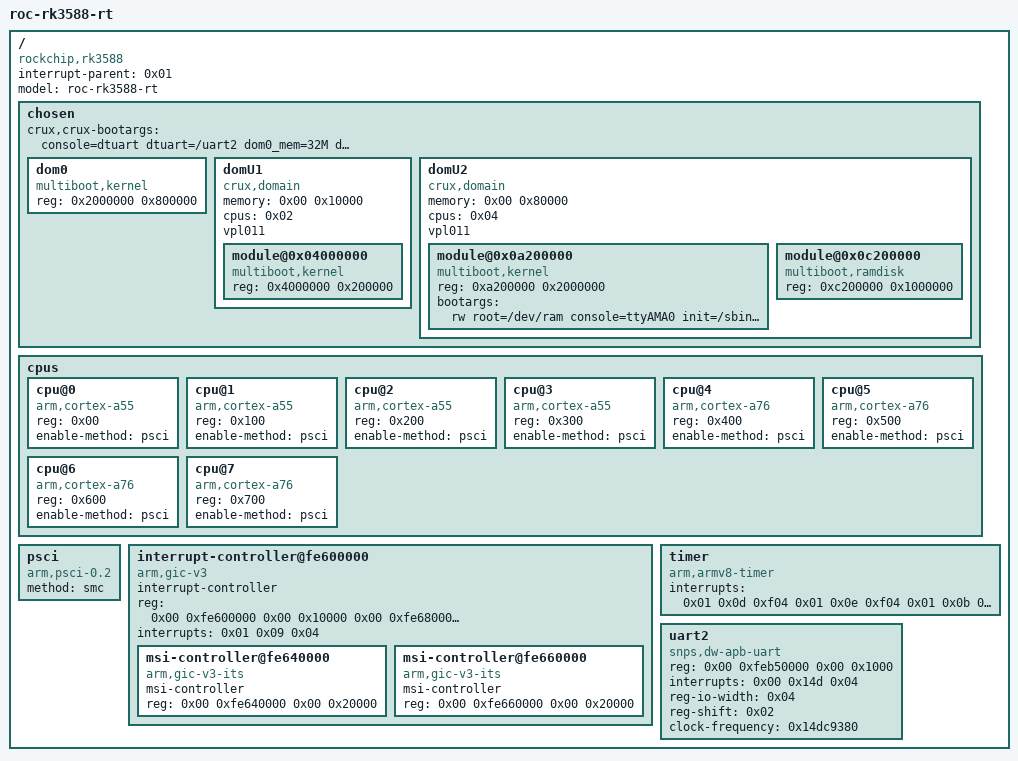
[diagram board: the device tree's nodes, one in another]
/dts-v1/;

/ {
	#address-cells = <0x02>;
	#size-cells = <0x02>;
	interrupt-parent = <0x01>;
	compatible = "rockchip,rk3588";
	model = "roc-rk3588-rt";

	chosen {
		#address-cells = <0x01>;
		#size-cells = <0x01>;
		crux,crux-bootargs = "console=dtuart dtuart=/uart2 dom0_mem=32M dom0_max_vcpus=1 sched=rtds bootscrub=0";

		dom0 {
			compatible = "multiboot,kernel\0multiboot,module";
			reg = <0x2000000 0x800000>;
		};

		domU1 {
			compatible = "crux,domain";
			memory = <0x00 0x10000>;
			cpus = <0x02>;
			vpl011;

			module@0x04000000 {
				compatible = "multiboot,kernel\0multiboot,module";
				reg = <0x4000000 0x200000>;
			};
		};

		domU2 {
			compatible = "crux,domain";
			memory = <0x00 0x80000>;
			cpus = <0x04>;
			vpl011;

			module@0x0a200000 {
				compatible = "multiboot,kernel\0multiboot,module";
				reg = <0xa200000 0x2000000>;
				bootargs = "rw root=/dev/ram console=ttyAMA0 init=/sbin/init";
			};

			module@0x0c200000 {
				compatible = "multiboot,ramdisk\0multiboot,module";
				reg = <0xc200000 0x1000000>;
			};
		};
	};

	cpus {
		#address-cells = <0x01>;
		#size-cells = <0x00>;

		cpu@0 {
			device_type = "cpu";
			compatible = "arm,cortex-a55";
			reg = <0x00>;
			enable-method = "psci";
		};

		cpu@1 {
			device_type = "cpu";
			compatible = "arm,cortex-a55";
			reg = <0x100>;
			enable-method = "psci";
		};

		cpu@2 {
			device_type = "cpu";
			compatible = "arm,cortex-a55";
			reg = <0x200>;
			enable-method = "psci";
		};

		cpu@3 {
			device_type = "cpu";
			compatible = "arm,cortex-a55";
			reg = <0x300>;
			enable-method = "psci";
		};

		cpu@4 {
			device_type = "cpu";
			compatible = "arm,cortex-a76";
			reg = <0x400>;
			enable-method = "psci";
		};

		cpu@5 {
			device_type = "cpu";
			compatible = "arm,cortex-a76";
			reg = <0x500>;
			enable-method = "psci";
		};

		cpu@6 {
			device_type = "cpu";
			compatible = "arm,cortex-a76";
			reg = <0x600>;
			enable-method = "psci";
		};

		cpu@7 {
			device_type = "cpu";
			compatible = "arm,cortex-a76";
			reg = <0x700>;
			enable-method = "psci";
		};
	};

	psci {
		compatible = "arm,psci-0.2";
		method = "smc";
	};

	interrupt-controller@fe600000 {
		#interrupt-cells = <0x03>;
		#address-cells = <0x02>;
		#size-cells = <0x02>;
		interrupt-controller;
		ranges;
		compatible = "arm,gic-v3\0arm,gic";
		reg = <0x00 0xfe600000 0x00 0x10000 0x00 0xfe680000 0x00 0x100000>;
		interrupts = <0x01 0x09 0x04>;
		phandle = <0x01>;

		msi-controller@fe640000 {
			compatible = "arm,gic-v3-its";
			msi-controller;
			#msi-cells = <0x01>;
			reg = <0x00 0xfe640000 0x00 0x20000>;
		};

		msi-controller@fe660000 {
			compatible = "arm,gic-v3-its";
			msi-controller;
			#msi-cells = <0x01>;
			reg = <0x00 0xfe660000 0x00 0x20000>;
		};
	};

	timer {
		compatible = "arm,armv8-timer";
		interrupts = <0x01 0x0d 0xf04 0x01 0x0e 0xf04 0x01 0x0b 0xf04 0x01 0x0a 0xf04>;
	};

	uart2 {
		compatible = "snps,dw-apb-uart\0ns16550";
		reg = <0x00 0xfeb50000 0x00 0x1000>;
		interrupts = <0x00 0x14d 0x04>;
		reg-io-width = <0x04>;
		reg-shift = <0x02>;
		clock-frequency = <0x14dc9380>;
	};
};
